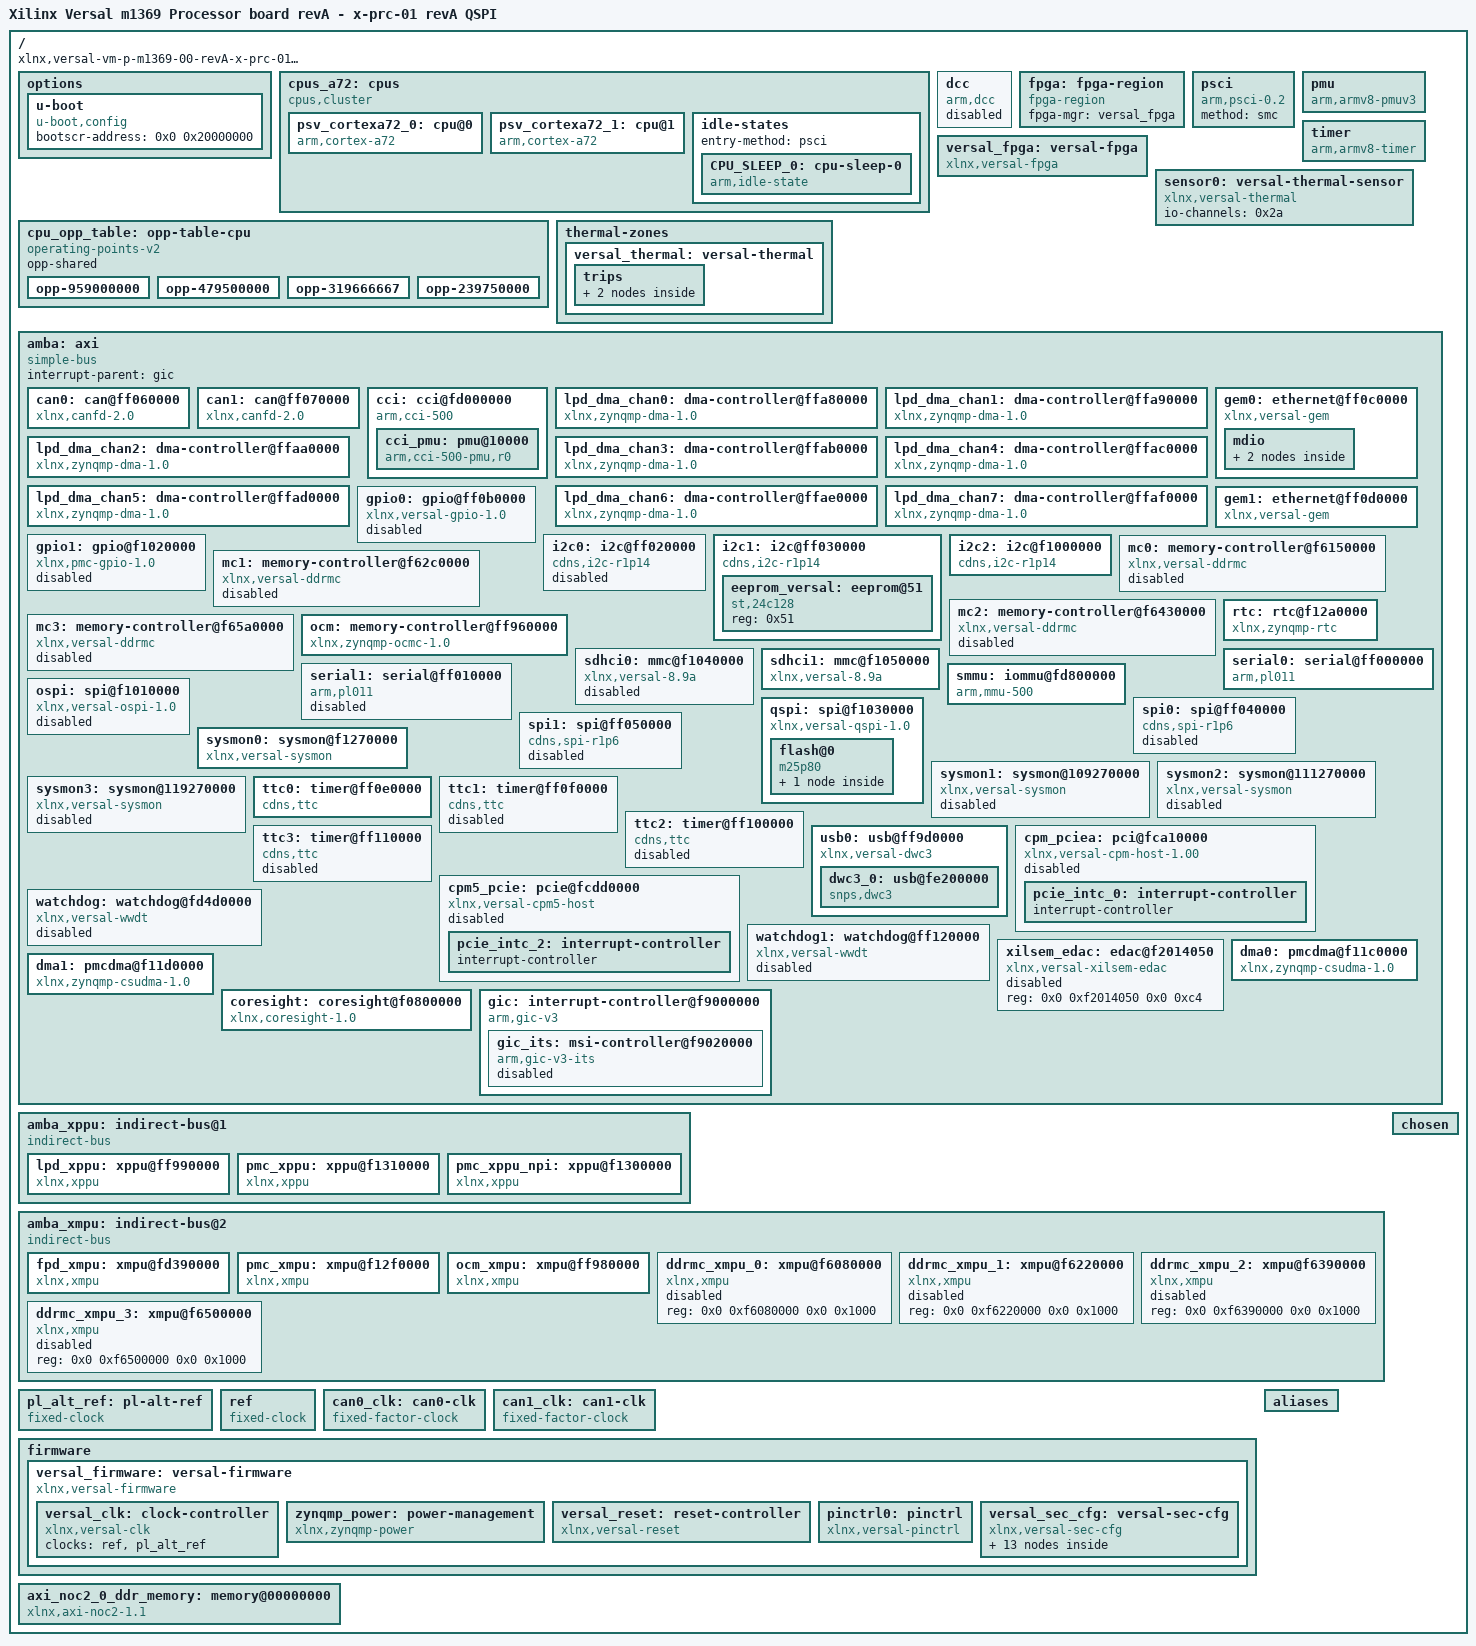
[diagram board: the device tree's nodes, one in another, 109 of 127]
/dts-v1/;
/ {
        compatible = "xlnx,versal-vm-p-m1369-00-revA-x-prc-01-revA", "xlnx,versal-vm-p-m1369-00-revA", "xlnx,versal-vm-p-m1369-00", "xlnx,versal-vm-p-m1369", "xlnx,versal";
        #address-cells = <0x2>;
        #size-cells = <0x2>;
        model = "Xilinx Versal m1369 Processor board revA - x-prc-01 revA QSPI";
        device_id = "xcvm2152";
        slrcount = <0x1>;
        family = "Versal";
        speed_grade = "1LP";

        options {

                u-boot {
                        compatible = "u-boot,config";
                        bootscr-address = <0x0 0x20000000>;
                };
        };

        cpus_a72: cpus {
                #address-cells = <0x1>;
                #size-cells = <0x0>;
                compatible = "cpus,cluster";
                #ranges-address-cells = <0x2>;
                #ranges-size-cells = <0x2>;
                phandle = <0x88>;

                psv_cortexa72_0: cpu@0 {
                        compatible = "arm,cortex-a72", "arm,armv8";
                        device_type = "cpu";
                        enable-method = "psci";
                        operating-points-v2 = <&cpu_opp_table>;
                        reg = <0x0>;
                        cpu-idle-states = <&CPU_SLEEP_0>;
                        power-domains = <&versal_firmware 0x18110003>;
                        clocks = <&versal_clk 0x4d>;
                        xlnx,timestamp-clk-freq = <0x2faf0800>;
                        xlnx,pss-ref-clk-freq = <0x1fc9f08>;
                        stamp-frequency = <0x2faf0800>;
                        xlnx,ip-name = "psv_cortexa72";
                        xlnx,cpu-clk-freq-hz = <0x2faf0800>;
                        cpu-frequency = <0x2faf0800>;
                        bus-handle = <0x1>;
                        phandle = <0x89>;
                };

                psv_cortexa72_1: cpu@1 {
                        compatible = "arm,cortex-a72", "arm,armv8";
                        device_type = "cpu";
                        enable-method = "psci";
                        operating-points-v2 = <&cpu_opp_table>;
                        reg = <0x1>;
                        cpu-idle-states = <&CPU_SLEEP_0>;
                        power-domains = <&versal_firmware 0x18110004>;
                        xlnx,timestamp-clk-freq = <0x2faf0800>;
                        xlnx,pss-ref-clk-freq = <0x1fc9f08>;
                        stamp-frequency = <0x2faf0800>;
                        xlnx,ip-name = "psv_cortexa72";
                        xlnx,cpu-clk-freq-hz = <0x2faf0800>;
                        cpu-frequency = <0x2faf0800>;
                        bus-handle = <0x1>;
                        phandle = <0x8a>;
                };

                idle-states {
                        entry-method = "psci";

                        CPU_SLEEP_0: cpu-sleep-0 {
                                compatible = "arm,idle-state";
                                arm,psci-suspend-param = <0x40000000>;
                                local-timer-stop;
                                entry-latency-us = <0x12c>;
                                exit-latency-us = <0x258>;
                                min-residency-us = <0x2710>;
                                phandle = <0x62>;
                        };
                };
        };

        cpu_opp_table: opp-table-cpu {
                compatible = "operating-points-v2";
                opp-shared;
                phandle = <0x61>;

                opp-959000000 {
                        opp-hz = <0x0 0x39292dc0>;
                        clock-latency-ns = <0x7a120>;
                        opp-microvolt = <0xf4240>;
                };

                opp-479500000 {
                        opp-hz = <0x0 0x1c9496e0>;
                        clock-latency-ns = <0x7a120>;
                        opp-microvolt = <0xf4240>;
                };

                opp-319666667 {
                        opp-hz = <0x0 0x130db9eb>;
                        clock-latency-ns = <0x7a120>;
                        opp-microvolt = <0xf4240>;
                };

                opp-239750000 {
                        opp-hz = <0x0 0xe4a4b70>;
                        clock-latency-ns = <0x7a120>;
                        opp-microvolt = <0xf4240>;
                };
        };

        dcc: dcc {
                compatible = "arm,dcc";
                status = "disabled";
                bootph-all;
                phandle = <0x93>;
        };

        fpga: fpga-region {
                compatible = "fpga-region";
                fpga-mgr = <&versal_fpga>;
                #address-cells = <0x2>;
                #size-cells = <0x2>;
                phandle = <0x94>;
        };

        psci: psci {
                compatible = "arm,psci-0.2";
                method = "smc";
                phandle = <0x95>;
        };

        pmu {
                compatible = "arm,armv8-pmuv3";
                interrupt-parent = <&gic>;
                interrupts = <0x1 0x7 0x304>;
        };

        timer: timer {
                compatible = "arm,armv8-timer";
                interrupt-parent = <&gic>;
                interrupts = <0x1 0xd 0x4 0x1 0xe 0x4 0x1 0xb 0x4 0x1 0xa 0x4>;
                phandle = <0x96>;
        };

        versal_fpga: versal-fpga {
                compatible = "xlnx,versal-fpga";
                phandle = <0x7b>;
        };

        sensor0: versal-thermal-sensor {
                compatible = "xlnx,versal-thermal";
                #thermal-sensor-cells = <0x0>;
                io-channels = <0x2a>;
                io-channel-names = "sysmon-temp-channel";
                phandle = <0x7d>;
        };

        thermal-zones {

                versal_thermal: versal-thermal {
                        polling-delay-passive = <0xfa>;
                        polling-delay = <0x3e8>;
                        thermal-sensors = <0x7d>;
                        phandle = <0x97>;

                        trips {

                                temp_alert: temp-alert {
                                        temperature = <0x11170>;
                                        hysteresis = <0x0>;
                                        type = "passive";
                                        phandle = <0x98>;
                                };

                                ot_crit: ot-crit {
                                        temperature = <0x1e848>;
                                        hysteresis = <0x0>;
                                        type = "critical";
                                        phandle = <0x99>;
                                };
                        };
                };
        };

        amba: axi {
                compatible = "simple-bus";
                #address-cells = <0x2>;
                #size-cells = <0x2>;
                ranges;
                interrupt-parent = <&gic>;
                bootph-all;
                phandle = <0x1>;

                can0: can@ff060000 {
                        compatible = "xlnx,canfd-2.0";
                        status = "okay";
                        reg = <0x0 0xff060000 0x0 0x6000>;
                        interrupts = <0x0 0x14 0x4>;
                        interrupt-parent = <&gic>;
                        clock-names = "can_clk", "s_axi_aclk";
                        rx-fifo-depth = <0x40>;
                        tx-mailbox-count = <0x20>;
                        clocks = <&can0_clk>,
                         <&versal_clk 0x52>;
                        power-domains = <&versal_firmware 0x1822401f>;
                        xlnx,can-rx-dpth = <0x40>;
                        xlnx,num-of-rx-mb-buf = <0x30>;
                        xlnx,can-clk-freq-hz = <0x98524b3>;
                        xlnx,ip-name = "psv_canfd";
                        xlnx,rx-mode = <0x0>;
                        xlnx,can-tx-dpth = <0x20>;
                        xlnx,num-of-tx-buf = <0x20>;
                        xlnx,can-board-interface = "custom";
                        phandle = <0x43>;
                };

                can1: can@ff070000 {
                        compatible = "xlnx,canfd-2.0";
                        status = "okay";
                        reg = <0x0 0xff070000 0x0 0x6000>;
                        interrupts = <0x0 0x15 0x4>;
                        interrupt-parent = <&gic>;
                        clock-names = "can_clk", "s_axi_aclk";
                        rx-fifo-depth = <0x40>;
                        tx-mailbox-count = <0x20>;
                        clocks = <&can1_clk>,
                         <&versal_clk 0x52>;
                        power-domains = <&versal_firmware 0x18224020>;
                        xlnx,can-rx-dpth = <0x40>;
                        xlnx,num-of-rx-mb-buf = <0x30>;
                        xlnx,can-clk-freq-hz = <0x98524b3>;
                        xlnx,ip-name = "psv_canfd";
                        xlnx,rx-mode = <0x0>;
                        xlnx,can-tx-dpth = <0x20>;
                        xlnx,num-of-tx-buf = <0x20>;
                        xlnx,can-board-interface = "custom";
                        phandle = <0x44>;
                };

                cci: cci@fd000000 {
                        compatible = "arm,cci-500";
                        status = "okay";
                        reg = <0x0 0xfd000000 0x0 0x10000>;
                        ranges = <0x0 0x0 0xfd000000 0xa0000>;
                        #address-cells = <0x1>;
                        #size-cells = <0x1>;
                        xlnx,ip-name = "psv_fpd_maincci";
                        phandle = <0x34>;

                        cci_pmu: pmu@10000 {
                                compatible = "arm,cci-500-pmu,r0";
                                reg = <0x10000 0x90000>;
                                interrupt-parent = <&gic>;
                                interrupts = <0x0 0x6a 0x4 0x0 0x6a 0x4 0x0 0x6a 0x4 0x0 0x6a 0x4 0x0 0x6a 0x4 0x0 0x6a 0x4 0x0 0x6a 0x4 0x0 0x6a 0x4>;
                                phandle = <0x9a>;
                        };
                };

                lpd_dma_chan0: dma-controller@ffa80000 {
                        compatible = "xlnx,zynqmp-dma-1.0";
                        status = "okay";
                        reg = <0x0 0xffa80000 0x0 0x1000>;
                        interrupts = <0x0 0x3c 0x4>;
                        interrupt-parent = <&gic>;
                        clock-names = "clk_main", "clk_apb";
                        xlnx,dma-type = <0x1>;
                        #dma-cells = <0x1>;
                        xlnx,bus-width = <0x40>;
                        clocks = <&versal_clk 0x51>,
                         <&versal_clk 0x52>;
                        power-domains = <&versal_firmware 0x18224035>;
                        xlnx,is-cache-coherent = <0x0>;
                        xlnx,ip-name = "psv_adma";
                        xlnx,dma-mode = <0x1>;
                        phandle = <0x55>;
                };

                lpd_dma_chan1: dma-controller@ffa90000 {
                        compatible = "xlnx,zynqmp-dma-1.0";
                        status = "okay";
                        reg = <0x0 0xffa90000 0x0 0x1000>;
                        interrupts = <0x0 0x3d 0x4>;
                        interrupt-parent = <&gic>;
                        clock-names = "clk_main", "clk_apb";
                        xlnx,dma-type = <0x1>;
                        #dma-cells = <0x1>;
                        xlnx,bus-width = <0x40>;
                        clocks = <&versal_clk 0x51>,
                         <&versal_clk 0x52>;
                        power-domains = <&versal_firmware 0x18224036>;
                        xlnx,is-cache-coherent = <0x0>;
                        xlnx,ip-name = "psv_adma";
                        xlnx,dma-mode = <0x1>;
                        phandle = <0x56>;
                };

                lpd_dma_chan2: dma-controller@ffaa0000 {
                        compatible = "xlnx,zynqmp-dma-1.0";
                        status = "okay";
                        reg = <0x0 0xffaa0000 0x0 0x1000>;
                        interrupts = <0x0 0x3e 0x4>;
                        interrupt-parent = <&gic>;
                        clock-names = "clk_main", "clk_apb";
                        xlnx,dma-type = <0x1>;
                        #dma-cells = <0x1>;
                        xlnx,bus-width = <0x40>;
                        clocks = <&versal_clk 0x51>,
                         <&versal_clk 0x52>;
                        power-domains = <&versal_firmware 0x18224037>;
                        xlnx,is-cache-coherent = <0x0>;
                        xlnx,ip-name = "psv_adma";
                        xlnx,dma-mode = <0x1>;
                        phandle = <0x57>;
                };

                lpd_dma_chan3: dma-controller@ffab0000 {
                        compatible = "xlnx,zynqmp-dma-1.0";
                        status = "okay";
                        reg = <0x0 0xffab0000 0x0 0x1000>;
                        interrupts = <0x0 0x3f 0x4>;
                        interrupt-parent = <&gic>;
                        clock-names = "clk_main", "clk_apb";
                        xlnx,dma-type = <0x1>;
                        #dma-cells = <0x1>;
                        xlnx,bus-width = <0x40>;
                        clocks = <&versal_clk 0x51>,
                         <&versal_clk 0x52>;
                        power-domains = <&versal_firmware 0x18224038>;
                        xlnx,is-cache-coherent = <0x0>;
                        xlnx,ip-name = "psv_adma";
                        xlnx,dma-mode = <0x1>;
                        phandle = <0x58>;
                };

                lpd_dma_chan4: dma-controller@ffac0000 {
                        compatible = "xlnx,zynqmp-dma-1.0";
                        status = "okay";
                        reg = <0x0 0xffac0000 0x0 0x1000>;
                        interrupts = <0x0 0x40 0x4>;
                        interrupt-parent = <&gic>;
                        clock-names = "clk_main", "clk_apb";
                        xlnx,dma-type = <0x1>;
                        #dma-cells = <0x1>;
                        xlnx,bus-width = <0x40>;
                        clocks = <&versal_clk 0x51>,
                         <&versal_clk 0x52>;
                        power-domains = <&versal_firmware 0x18224039>;
                        xlnx,is-cache-coherent = <0x0>;
                        xlnx,ip-name = "psv_adma";
                        xlnx,dma-mode = <0x1>;
                        phandle = <0x59>;
                };

                lpd_dma_chan5: dma-controller@ffad0000 {
                        compatible = "xlnx,zynqmp-dma-1.0";
                        status = "okay";
                        reg = <0x0 0xffad0000 0x0 0x1000>;
                        interrupts = <0x0 0x41 0x4>;
                        interrupt-parent = <&gic>;
                        clock-names = "clk_main", "clk_apb";
                        xlnx,dma-type = <0x1>;
                        #dma-cells = <0x1>;
                        xlnx,bus-width = <0x40>;
                        clocks = <&versal_clk 0x51>,
                         <&versal_clk 0x52>;
                        power-domains = <&versal_firmware 0x1822403a>;
                        xlnx,is-cache-coherent = <0x0>;
                        xlnx,ip-name = "psv_adma";
                        xlnx,dma-mode = <0x1>;
                        phandle = <0x5a>;
                };

                lpd_dma_chan6: dma-controller@ffae0000 {
                        compatible = "xlnx,zynqmp-dma-1.0";
                        status = "okay";
                        reg = <0x0 0xffae0000 0x0 0x1000>;
                        interrupts = <0x0 0x42 0x4>;
                        interrupt-parent = <&gic>;
                        clock-names = "clk_main", "clk_apb";
                        xlnx,dma-type = <0x1>;
                        #dma-cells = <0x1>;
                        xlnx,bus-width = <0x40>;
                        clocks = <&versal_clk 0x51>,
                         <&versal_clk 0x52>;
                        power-domains = <&versal_firmware 0x1822403b>;
                        xlnx,is-cache-coherent = <0x0>;
                        xlnx,ip-name = "psv_adma";
                        xlnx,dma-mode = <0x1>;
                        phandle = <0x5b>;
                };

                lpd_dma_chan7: dma-controller@ffaf0000 {
                        compatible = "xlnx,zynqmp-dma-1.0";
                        status = "okay";
                        reg = <0x0 0xffaf0000 0x0 0x1000>;
                        interrupts = <0x0 0x43 0x4>;
                        interrupt-parent = <&gic>;
                        clock-names = "clk_main", "clk_apb";
                        xlnx,dma-type = <0x1>;
                        #dma-cells = <0x1>;
                        xlnx,bus-width = <0x40>;
                        clocks = <&versal_clk 0x51>,
                         <&versal_clk 0x52>;
                        power-domains = <&versal_firmware 0x1822403c>;
                        xlnx,is-cache-coherent = <0x0>;
                        xlnx,ip-name = "psv_adma";
                        xlnx,dma-mode = <0x1>;
                        phandle = <0x5c>;
                };

                gem0: ethernet@ff0c0000 {
                        compatible = "xlnx,versal-gem", "cdns,gem";
                        status = "okay";
                        reg = <0x0 0xff0c0000 0x0 0x1000>;
                        interrupts = <0x0 0x38 0x4 0x0 0x38 0x4>;
                        interrupt-parent = <&gic>;
                        clock-names = "pclk", "hclk", "tx_clk", "rx_clk", "tsu_clk";
                        #address-cells = <0x1>;
                        #size-cells = <0x0>;
                        clocks = <&versal_clk 0x52>,
                         <&versal_clk 0x58>,
                         <&versal_clk 0x31>,
                         <&versal_clk 0x30>,
                         <&versal_clk 0x2b>;
                        power-domains = <&versal_firmware 0x18224019>;
                        xlnx,has-mdio = <0x1>;
                        xlnx,is-cache-coherent = <0x0>;
                        xlnx,gem-board-interface = "custom";
                        phy-mode = "rgmii-id";
                        xlnx,enet-slcr-1000mbps-div0 = <0x7>;
                        xlnx,enet-slcr-10mbps-div0 = <0x15e>;
                        xlnx,enet-tsu-clk-freq-hz = <0xe47b705>;
                        xlnx,ip-name = "psv_ethernet";
                        xlnx,eth-mode = "RGMII";
                        xlnx,enet-clk-freq-hz = <0x7735464>;
                        xlnx,enet-slcr-100mbps-div0 = <0x23>;
                        phy-handle = <0x80>;
                        phandle = <0x47>;

                        mdio: mdio {
                                #address-cells = <0x1>;
                                #size-cells = <0x0>;
                                phandle = <0x9b>;

                                phy1: phy@1 {
                                        #phy-cells = <0x1>;
                                        compatible = "ethernet-phy-id2000.a231";
                                        reg = <0x1>;
                                        ti,rx-internal-delay = <0xb>;
                                        ti,tx-internal-delay = <0xa>;
                                        ti,fifo-depth = <0x1>;
                                        ti,dp83867-rxctrl-strap-quirk;
                                        phandle = <0x80>;
                                };

                                phy2: phy@2 {
                                        #phy-cells = <0x1>;
                                        compatible = "ethernet-phy-id2000.a231";
                                        reg = <0x2>;
                                        ti,rx-internal-delay = <0xb>;
                                        ti,tx-internal-delay = <0xa>;
                                        ti,fifo-depth = <0x1>;
                                        ti,dp83867-rxctrl-strap-quirk;
                                        phandle = <0x81>;
                                };
                        };
                };

                gem1: ethernet@ff0d0000 {
                        compatible = "xlnx,versal-gem", "cdns,gem";
                        status = "okay";
                        reg = <0x0 0xff0d0000 0x0 0x1000>;
                        interrupts = <0x0 0x3a 0x4 0x0 0x3a 0x4>;
                        interrupt-parent = <&gic>;
                        clock-names = "pclk", "hclk", "tx_clk", "rx_clk", "tsu_clk";
                        #address-cells = <0x1>;
                        #size-cells = <0x0>;
                        clocks = <&versal_clk 0x52>,
                         <&versal_clk 0x59>,
                         <&versal_clk 0x33>,
                         <&versal_clk 0x32>,
                         <&versal_clk 0x2b>;
                        power-domains = <&versal_firmware 0x1822401a>;
                        xlnx,has-mdio = <0x0>;
                        xlnx,is-cache-coherent = <0x0>;
                        xlnx,gem-board-interface = "custom";
                        phy-mode = "rgmii-id";
                        xlnx,enet-slcr-1000mbps-div0 = <0x7>;
                        xlnx,enet-slcr-10mbps-div0 = <0x15e>;
                        xlnx,enet-tsu-clk-freq-hz = <0xe47b705>;
                        xlnx,ip-name = "psv_ethernet";
                        xlnx,eth-mode = "RGMII";
                        xlnx,enet-clk-freq-hz = <0x7735464>;
                        xlnx,enet-slcr-100mbps-div0 = <0x23>;
                        phy-handle = <0x81>;
                        phandle = <0x48>;
                };

                gpio0: gpio@ff0b0000 {
                        compatible = "xlnx,versal-gpio-1.0";
                        status = "disabled";
                        reg = <0x0 0xff0b0000 0x0 0x1000>;
                        interrupts = <0x0 0xd 0x4>;
                        interrupt-parent = <&gic>;
                        #gpio-cells = <0x2>;
                        gpio-controller;
                        #interrupt-cells = <0x2>;
                        interrupt-controller;
                        clocks = <&versal_clk 0x52>;
                        power-domains = <&versal_firmware 0x18224023>;
                        phandle = <0x9c>;
                };

                gpio1: gpio@f1020000 {
                        compatible = "xlnx,pmc-gpio-1.0";
                        status = "disabled";
                        reg = <0x0 0xf1020000 0x0 0x1000>;
                        interrupts = <0x0 0x7a 0x4>;
                        interrupt-parent = <&gic>;
                        #gpio-cells = <0x2>;
                        gpio-controller;
                        #interrupt-cells = <0x2>;
                        interrupt-controller;
                        clocks = <&versal_clk 0x3d>;
                        power-domains = <&versal_firmware 0x1822402c>;
                        phandle = <0x9d>;
                };

                i2c0: i2c@ff020000 {
                        compatible = "cdns,i2c-r1p14";
                        status = "disabled";
                        reg = <0x0 0xff020000 0x0 0x1000>;
                        interrupts = <0x0 0xe 0x4>;
                        interrupt-parent = <&gic>;
                        clock-frequency = <0x186a0>;
                        #address-cells = <0x1>;
                        #size-cells = <0x0>;
                        clocks = <&versal_clk 0x62>;
                        power-domains = <&versal_firmware 0x1822401d>;
                        phandle = <0x9e>;
                };

                i2c1: i2c@ff030000 {
                        compatible = "cdns,i2c-r1p14";
                        status = "okay";
                        reg = <0x0 0xff030000 0x0 0x1000>;
                        interrupts = <0x0 0xf 0x4>;
                        interrupt-parent = <&gic>;
                        clock-frequency = <0x61a80>;
                        #address-cells = <0x1>;
                        #size-cells = <0x0>;
                        clocks = <&versal_clk 0x63>;
                        power-domains = <&versal_firmware 0x1822401e>;
                        xlnx,clock-freq = <0x5f5dd19>;
                        xlnx,i2c-clk-freq-hz = <0x5f5dd19>;
                        xlnx,ip-name = "psv_i2c";
                        xlnx,iic-board-interface = "custom";
                        phandle = <0x42>;

                        eeprom_versal: eeprom@51 {
                                compatible = "st,24c128", "atmel,24c128";
                                reg = <0x51>;
                                phandle = <0x9f>;
                        };
                };

                i2c2: i2c@f1000000 {
                        compatible = "cdns,i2c-r1p14";
                        status = "okay";
                        reg = <0x0 0xf1000000 0x0 0x1000>;
                        interrupts = <0x0 0x7b 0x4>;
                        interrupt-parent = <&gic>;
                        clock-frequency = <0x186a0>;
                        #address-cells = <0x1>;
                        #size-cells = <0x0>;
                        clocks = <&versal_clk 0x3e>;
                        power-domains = <&versal_firmware 0x1822402d>;
                        xlnx,clock-freq = <0x5f5dd19>;
                        xlnx,i2c-clk-freq-hz = <0x5f5dd19>;
                        xlnx,ip-name = "psv_pmc_i2c";
                        phandle = <0x1b>;
                };

                mc0: memory-controller@f6150000 {
                        compatible = "xlnx,versal-ddrmc";
                        status = "disabled";
                        reg = <0x0 0xf6150000 0x0 0x2000 0x0 0xf6070000 0x0 0x20000>;
                        reg-names = "base", "noc";
                        interrupts = <0x0 0x93 0x4>;
                        interrupt-parent = <&gic>;
                        phandle = <0xa0>;
                };

                mc1: memory-controller@f62c0000 {
                        compatible = "xlnx,versal-ddrmc";
                        status = "disabled";
                        reg = <0x0 0xf62c0000 0x0 0x2000 0x0 0xf6210000 0x0 0x20000>;
                        reg-names = "base", "noc";
                        interrupts = <0x0 0x93 0x4>;
                        interrupt-parent = <&gic>;
                        phandle = <0xa1>;
                };

                mc2: memory-controller@f6430000 {
                        compatible = "xlnx,versal-ddrmc";
                        status = "disabled";
                        reg = <0x0 0xf6430000 0x0 0x2000 0x0 0xf6380000 0x0 0x20000>;
                        reg-names = "base", "noc";
                        interrupts = <0x0 0x93 0x4>;
                        interrupt-parent = <&gic>;
                        phandle = <0xa2>;
                };

                mc3: memory-controller@f65a0000 {
                        compatible = "xlnx,versal-ddrmc";
                        status = "disabled";
                        reg = <0x0 0xf65a0000 0x0 0x2000 0x0 0xf64f0000 0x0 0x20000>;
                        reg-names = "base", "noc";
                        interrupts = <0x0 0x93 0x4>;
                        interrupt-parent = <&gic>;
                        phandle = <0xa3>;
                };

                ocm: memory-controller@ff960000 {
                        compatible = "xlnx,zynqmp-ocmc-1.0";
                        reg = <0x0 0xff960000 0x0 0x1000>;
                        interrupts = <0x0 0xa 0x4>;
                        interrupt-parent = <&gic>;
                        phandle = <0xa4>;
                };

                rtc: rtc@f12a0000 {
                        compatible = "xlnx,zynqmp-rtc";
                        status = "okay";
                        reg = <0x0 0xf12a0000 0x0 0x100>;
                        interrupt-names = "alarm", "sec";
                        interrupts = <0x0 0x8e 0x4 0x0 0x8f 0x4>;
                        interrupt-parent = <&gic>;
                        calibration = <0x7fff>;
                        power-domains = <&versal_firmware 0x18224034>;
                        xlnx,ip-name = "psv_pmc_rtc";
                        phandle = <0x2b>;
                };

                sdhci0: mmc@f1040000 {
                        compatible = "xlnx,versal-8.9a", "arasan,sdhci-8.9a";
                        status = "disabled";
                        reg = <0x0 0xf1040000 0x0 0x10000>;
                        interrupts = <0x0 0x7e 0x4>;
                        interrupt-parent = <&gic>;
                        clock-names = "clk_xin", "clk_ahb", "gate";
                        #clock-cells = <0x1>;
                        clock-output-names = "clk_out_sd0", "clk_in_sd0";
                        clocks = <&versal_clk 0x3b>,
                         <&versal_clk 0x52>,
                         <&versal_clk 0x4a>;
                        power-domains = <&versal_firmware 0x1822402e>;
                        no-1-8-v;
                        phandle = <0xa5>;
                };

                sdhci1: mmc@f1050000 {
                        compatible = "xlnx,versal-8.9a", "arasan,sdhci-8.9a";
                        status = "okay";
                        reg = <0x0 0xf1050000 0x0 0x10000>;
                        interrupts = <0x0 0x80 0x4>;
                        interrupt-parent = <&gic>;
                        clock-names = "clk_xin", "clk_ahb", "gate";
                        #clock-cells = <0x1>;
                        clock-output-names = "clk_out_sd1", "clk_in_sd1";
                        clocks = <&versal_clk 0x3c>,
                         <&versal_clk 0x52>,
                         <&versal_clk 0x4a>;
                        power-domains = <&versal_firmware 0x1822402f>;
                        xlnx,sd-board-interface = "custom";
                        xlnx,is-cache-coherent = <0x0>;
                        xlnx,clk-50-ddr-otap-dly = <0x3>;
                        xlnx,clk-50-sdr-itap-dly = <0x2c>;
                        xlnx,has-emio = <0x0>;
                        clock-frequency = <0xbebba31>;
                        xlnx,clk-100-sdr-otap-dly = <0x3>;
                        xlnx,mio-bank = <0x1>;
                        xlnx,ip-name = "psv_pmc_sd";
                        xlnx,bus-width = <0x8>;
                        xlnx,card-detect = <0x1>;
                        xlnx,has-wp = <0x1>;
                        xlnx,has-cd = <0x1>;
                        xlnx,slot-type = <0x3>;
                        xlnx,clk-50-sdr-otap-dly = <0x4>;
                        xlnx,clk-50-ddr-itap-dly = <0x36>;
                        xlnx,has-power = <0x1>;
                        xlnx,clk-200-sdr-otap-dly = <0x2>;
                        xlnx,sdio-clk-freq-hz = <0xbebba31>;
                        xlnx,write-protect = <0x1>;
                        no-1-8-v;
                        phandle = <0x1d>;
                };

                serial0: serial@ff000000 {
                        compatible = "arm,pl011", "arm,primecell";
                        status = "okay";
                        reg = <0x0 0xff000000 0x0 0x1000>;
                        interrupts = <0x0 0x12 0x4>;
                        interrupt-parent = <&gic>;
                        reg-io-width = <0x4>;
                        clock-names = "uartclk", "apb_pclk";
                        bootph-all;
                        clocks = <&versal_clk 0x5c>,
                         <&versal_clk 0x52>;
                        power-domains = <&versal_firmware 0x18224021>;
                        xlnx,clock-freq = <0x5f5dd19>;
                        u-boot,dm-pre-reloc;
                        xlnx,uart-board-interface = "custom";
                        xlnx,has-modem = <0x0>;
                        xlnx,ip-name = "psv_sbsauart";
                        xlnx,baudrate = <0x1c200>;
                        cts-override;
                        port-number = <0x0>;
                        xlnx,uart-clk-freq-hz = <0x5f5dd19>;
                        phandle = <0x41>;
                };

                serial1: serial@ff010000 {
                        compatible = "arm,pl011", "arm,primecell";
                        status = "disabled";
                        reg = <0x0 0xff010000 0x0 0x1000>;
                        interrupts = <0x0 0x13 0x4>;
                        interrupt-parent = <&gic>;
                        reg-io-width = <0x4>;
                        clock-names = "uartclk", "apb_pclk";
                        bootph-all;
                        clocks = <&versal_clk 0x5d>,
                         <&versal_clk 0x52>;
                        power-domains = <&versal_firmware 0x18224022>;
                        phandle = <0xa6>;
                };

                smmu: iommu@fd800000 {
                        compatible = "arm,mmu-500";
                        status = "okay";
                        reg = <0x0 0xfd800000 0x0 0x40000>;
                        stream-match-mask = <0x7c00>;
                        #iommu-cells = <0x1>;
                        #global-interrupts = <0x1>;
                        interrupts = <0x0 0x6b 0x4 0x0 0x6b 0x4 0x0 0x6b 0x4 0x0 0x6b 0x4 0x0 0x6b 0x4 0x0 0x6b 0x4 0x0 0x6b 0x4 0x0 0x6b 0x4 0x0 0x6b 0x4 0x0 0x6b 0x4 0x0 0x6b 0x4 0x0 0x6b 0x4 0x0 0x6b 0x4 0x0 0x6b 0x4 0x0 0x6b 0x4 0x0 0x6b 0x4 0x0 0x6b 0x4 0x0 0x6b 0x4 0x0 0x6b 0x4 0x0 0x6b 0x4 0x0 0x6b 0x4 0x0 0x6b 0x4 0x0 0x6b 0x4 0x0 0x6b 0x4 0x0 0x6b 0x4 0x0 0x6b 0x4 0x0 0x6b 0x4 0x0 0x6b 0x4 0x0 0x6b 0x4 0x0 0x6b 0x4 0x0 0x6b 0x4 0x0 0x6b 0x4 0x0 0x6b 0x4>;
                        interrupt-parent = <&gic>;
                        xlnx,ip-name = "psv_fpd_smmutcu";
                        phandle = <0x3f>;
                };

                ospi: spi@f1010000 {
                        compatible = "xlnx,versal-ospi-1.0", "cdns,qspi-nor";
                        status = "disabled";
                        reg = <0x0 0xf1010000 0x0 0x10000 0x0 0xc0000000 0x0 0x20000000>;
                        interrupts = <0x0 0x7c 0x4>;
                        interrupt-parent = <&gic>;
                        cdns,fifo-depth = <0x100>;
                        cdns,fifo-width = <0x4>;
                        cdns,is-dma = <0x1>;
                        cdns,trigger-address = <0xc0000000>;
                        #address-cells = <0x1>;
                        #size-cells = <0x0>;
                        clocks = <&versal_clk 0x3a>;
                        power-domains = <&versal_firmware 0x1822402a>;
                        reset-names = "qspi";
                        resets = <&versal_reset 0xc10402e>;
                        phandle = <0xa7>;
                };

                qspi: spi@f1030000 {
                        compatible = "xlnx,versal-qspi-1.0";
                        status = "okay";
                        reg = <0x0 0xf1030000 0x0 0x1000>;
                        interrupts = <0x0 0x7d 0x4>;
                        interrupt-parent = <&gic>;
                        clock-names = "ref_clk", "pclk";
                        #address-cells = <0x1>;
                        #size-cells = <0x0>;
                        clocks = <&versal_clk 0x39>,
                         <&versal_clk 0x52>;
                        power-domains = <&versal_firmware 0x1822402b>;
                        xlnx,is-cache-coherent = <0x0>;
                        xlnx,qspi-fbclk = <0x1>;
                        xlnx,baud-rate-div = <0x8>;
                        num-cs = <0x2>;
                        xlnx,qspi-clk-freq-hz = <0x11e19751>;
                        xlnx,bus-width = <0x2>;
                        xlnx,ip-name = "psv_pmc_qspi";
                        spi-rx-bus-width = <0x4>;
                        xlnx,connection-mode = <0x2>;
                        spi-tx-bus-width = <0x4>;
                        xlnx,clock-freq = <0x11e19751>;
                        xlnx,qspi-baud-rate-div = <0x8>;
                        xlnx,qspi-mode = <0x2>;
                        xlnx,qspi-bus-width = <0x2>;
                        is-dual = <0x1>;
                        phandle = <0x1c>;

                        flash@0 {
                                compatible = "m25p80", "jedec,spi-nor";
                                #address-cells = <0x1>;
                                #size-cells = <0x1>;
                                reg = <0x0 0x1>;
                                parallel-memories = <0x0 0x8000000 0x0 0x8000000>;
                                spi-tx-bus-width = <0x4>;
                                spi-rx-bus-width = <0x4>;
                                spi-max-frequency = <0x2160ec0>;

                                partition@0 {
                                        label = "spi0-flash0";
                                        reg = <0x0 0x8000000>;
                                };
                        };
                };

                spi0: spi@ff040000 {
                        compatible = "cdns,spi-r1p6";
                        status = "disabled";
                        reg = <0x0 0xff040000 0x0 0x1000>;
                        interrupts = <0x0 0x10 0x4>;
                        interrupt-parent = <&gic>;
                        clock-names = "ref_clk", "pclk";
                        #address-cells = <0x1>;
                        #size-cells = <0x0>;
                        clocks = <&versal_clk 0x5e>,
                         <&versal_clk 0x52>;
                        power-domains = <&versal_firmware 0x1822401b>;
                        phandle = <0xa8>;
                };

                spi1: spi@ff050000 {
                        compatible = "cdns,spi-r1p6";
                        status = "disabled";
                        reg = <0x0 0xff050000 0x0 0x1000>;
                        interrupts = <0x0 0x11 0x4>;
                        interrupt-parent = <&gic>;
                        clock-names = "ref_clk", "pclk";
                        #address-cells = <0x1>;
                        #size-cells = <0x0>;
                        clocks = <&versal_clk 0x5f>,
                         <&versal_clk 0x52>;
                        power-domains = <&versal_firmware 0x1822401c>;
                        phandle = <0xa9>;
                };

                sysmon0: sysmon@f1270000 {
                        compatible = "xlnx,versal-sysmon";
                        #io-channel-cells = <0x0>;
                        reg = <0x0 0xf1270000 0x0 0x4000>;
                        interrupts = <0x0 0x90 0x4>;
                        xlnx,numchannels = "";
                        #address-cells = <0x2>;
                        #size-cells = <0x2>;
                        xlnx,nodeid = <0x18224055>;
                        xlnx,sat-1-desc = "PMC , system , ADC";
                        xlnx,sat-63-desc = "PS , FPD , satellite";
                        xlnx,sat-9-x = <0x1b0b>;
                        xlnx,sat-9-y = <0x1d6e>;
                        xlnx,ip-name = "psv_pmc_sysmon";
                        xlnx,sat-9-desc = "VNOC , satellite";
                        xlnx,sat-10-x = <0x1b0b>;
                        xlnx,sat-10-y = <0x2961>;
                        xlnx,sat-2-x = <0x24>;
                        xlnx,sat-64-x = <0x24>;
                        xlnx,sat-13-desc = "Clocking , column , satellite";
                        xlnx,sat-2-y = <0xea8>;
                        xlnx,sat-64-y = <0xea8>;
                        xlnx,sat-14-x = <0xb78>;
                        xlnx,sat-6-desc = "VNOC , satellite";
                        xlnx,sat-14-y = <0x1b09>;
                        xlnx,sat-6-x = <0x30dd>;
                        xlnx,sat-6-y = <0x2961>;
                        xlnx,sat-10-desc = "VNOC , satellite";
                        xlnx,sat-3-desc = "X5IO , Satellite";
                        xlnx,sat-11-x = <0xb78>;
                        xlnx,sat-11-y = <0x2d2c>;
                        xlnx,sat-3-x = <0xddd>;
                        status = "okay";
                        xlnx,sat-3-y = <0x90c>;
                        xlnx,sat-7-x = <0x2898>;
                        xlnx,sat-8-desc = "VNOC , satellite";
                        xlnx,sat-7-y = <0x90c>;
                        xlnx,sat-12-desc = "Clocking , column , satellite";
                        xlnx,sat-5-desc = "VNOC , satellite";
                        xlnx,sat-2-desc = "PMC , user , ADC";
                        xlnx,sat-64-desc = "PS , LPD , satellite";
                        xlnx,sat-12-x = <0xb78>;
                        xlnx,sat-12-y = <0x26fd>;
                        xlnx,sat-4-x = <0x30dd>;
                        xlnx,sat-4-y = <0x117a>;
                        xlnx,sat-8-x = <0x1b0b>;
                        xlnx,sat-8-y = <0x117a>;
                        xlnx,sat-14-desc = "Clocking , column , satellite";
                        xlnx,sat-7-desc = "X5IO , Satellite";
                        xlnx,sat-11-desc = "Clocking , column , satellite";
                        xlnx,sat-1-x = <0x24>;
                        xlnx,sat-63-x = <0x24>;
                        xlnx,sat-1-y = <0xea8>;
                        xlnx,sat-63-y = <0xea8>;
                        xlnx,sat-4-desc = "VNOC , satellite";
                        xlnx,sat-13-x = <0xb78>;
                        xlnx,sat-13-y = <0x2138>;
                        xlnx,sat-5-x = <0x30dd>;
                        xlnx,sat-5-y = <0x1d6e>;
                        phandle = <0x2a>;
                };

                sysmon1: sysmon@109270000 {
                        compatible = "xlnx,versal-sysmon";
                        status = "disabled";
                        reg = <0x1 0x9270000 0x0 0x4000>;
                        xlnx,numchannels = "";
                        #address-cells = <0x1>;
                        #size-cells = <0x0>;
                        xlnx,nodeid = <0x18225055>;
                        phandle = <0xaa>;
                };

                sysmon2: sysmon@111270000 {
                        compatible = "xlnx,versal-sysmon";
                        status = "disabled";
                        reg = <0x1 0x11270000 0x0 0x4000>;
                        xlnx,numchannels = "";
                        #address-cells = <0x1>;
                        #size-cells = <0x0>;
                        xlnx,nodeid = <0x18226055>;
                        phandle = <0xab>;
                };

                sysmon3: sysmon@119270000 {
                        compatible = "xlnx,versal-sysmon";
                        status = "disabled";
                        reg = <0x1 0x19270000 0x0 0x4000>;
                        xlnx,numchannels = "";
                        #address-cells = <0x1>;
                        #size-cells = <0x0>;
                        xlnx,nodeid = <0x18227055>;
                        phandle = <0xac>;
                };

                ttc0: timer@ff0e0000 {
                        compatible = "cdns,ttc";
                        status = "okay";
                        interrupts = <0x0 0x25 0x4 0x0 0x26 0x4 0x0 0x27 0x4>;
                        interrupt-parent = <&gic>;
                        reg = <0x0 0xff0e0000 0x0 0x1000>;
                        timer-width = <0x20>;
                        clocks = <&versal_clk 0x27>;
                        power-domains = <&versal_firmware 0x18224024>;
                        xlnx,ttc-board-interface = "custom";
                        xlnx,ttc-clk2-freq-hz = <0x5f5dd19>;
                        xlnx,ttc-clk1-clksrc = <0x1>;
                        xlnx,clock-freq = <0x5f5dd19>;
                        xlnx,ttc-clk2-clksrc = <0x1>;
                        xlnx,ip-name = "psv_ttc";
                        xlnx,ttc-clk0-freq-hz = <0x5f5dd19>;
                        xlnx,ttc-clk1-freq-hz = <0x5f5dd19>;
                        xlnx,ttc-clk0-clksrc = <0x1>;
                        phandle = <0x49>;
                };

                ttc1: timer@ff0f0000 {
                        compatible = "cdns,ttc";
                        status = "disabled";
                        interrupts = <0x0 0x28 0x4 0x0 0x29 0x4 0x0 0x2a 0x4>;
                        interrupt-parent = <&gic>;
                        reg = <0x0 0xff0f0000 0x0 0x1000>;
                        timer-width = <0x20>;
                        clocks = <&versal_clk 0x28>;
                        power-domains = <&versal_firmware 0x18224025>;
                        phandle = <0xad>;
                };

                ttc2: timer@ff100000 {
                        compatible = "cdns,ttc";
                        status = "disabled";
                        interrupts = <0x0 0x2b 0x4 0x0 0x2c 0x4 0x0 0x2d 0x4>;
                        interrupt-parent = <&gic>;
                        reg = <0x0 0xff100000 0x0 0x1000>;
                        timer-width = <0x20>;
                        clocks = <&versal_clk 0x29>;
                        power-domains = <&versal_firmware 0x18224026>;
                        phandle = <0xae>;
                };

                ttc3: timer@ff110000 {
                        compatible = "cdns,ttc";
                        status = "disabled";
                        interrupts = <0x0 0x2e 0x4 0x0 0x2f 0x4 0x0 0x30 0x4>;
                        interrupt-parent = <&gic>;
                        reg = <0x0 0xff110000 0x0 0x1000>;
                        timer-width = <0x20>;
                        clocks = <&versal_clk 0x2a>;
                        power-domains = <&versal_firmware 0x18224027>;
                        phandle = <0xaf>;
                };

                usb0: usb@ff9d0000 {
                        compatible = "xlnx,versal-dwc3";
                        status = "okay";
                        reg = <0x0 0xff9d0000 0x0 0x100>;
                        clock-names = "bus_clk", "ref_clk";
                        ranges;
                        #address-cells = <0x2>;
                        #size-cells = <0x2>;
                        clocks = <&versal_clk 0x5b>,
                         <&versal_clk 0x68>;
                        power-domains = <&versal_firmware 0x18224018>;
                        resets = <&versal_reset 0xc104036>;
                        xlnx,ip-name = "psv_usb";
                        phandle = <0x54>;

                        dwc3_0: usb@fe200000 {
                                compatible = "snps,dwc3";
                                status = "okay";
                                reg = <0x0 0xfe200000 0x0 0x10000>;
                                interrupt-names = "host", "peripheral", "otg", "wakeup";
                                interrupts = <0x0 0x16 0x4 0x0 0x16 0x4 0x0 0x1a 0x4 0x0 0x4a 0x4>;
                                interrupt-parent = <&gic>;
                                snps,dis_u2_susphy_quirk;
                                snps,dis_u3_susphy_quirk;
                                snps,quirk-frame-length-adjustment = <0x20>;
                                clock-names = "ref";
                                clocks = <&versal_clk 0x5b>;
                                xlnx,is-cache-coherent = <0x0>;
                                xlnx,ip-name = "psv_usb_xhci";
                                xlnx,enable-superspeed = <0x0>;
                                dr_mode = "host";
                                maximum-speed = "high-speed";
                                snps,usb3_lpm_capable;
                                phy-names = "usb3-phy";
                                phandle = <0x40>;
                        };
                };

                cpm_pciea: pci@fca10000 {
                        device_type = "pci";
                        #address-cells = <0x3>;
                        #interrupt-cells = <0x1>;
                        #size-cells = <0x2>;
                        compatible = "xlnx,versal-cpm-host-1.00";
                        status = "disabled";
                        interrupt-map = <0x0 0x0 0x0 0x1 &pcie_intc_0 0x0>,
                         <0x0 0x0 0x0 0x2 &pcie_intc_0 0x1>,
                         <0x0 0x0 0x0 0x3 &pcie_intc_0 0x2>,
                         <0x0 0x0 0x0 0x4 &pcie_intc_0 0x3>;
                        interrupt-map-mask = <0x0 0x0 0x0 0x7>;
                        interrupt-names = "misc";
                        interrupts = <0x0 0x48 0x4>;
                        xlnx,csr-slcr = <0x6 0x0>;
                        xlnx,num-of-bars = <0x2>;
                        xlnx,port-type = <0x1>;
                        interrupt-parent = <&gic>;
                        bus-range = <0x0 0xff>;
                        ranges = <0x2000000 0x0 0xe0010000 0x0 0xe0010000 0x0 0x10000000 0x43000000 0x80 0x0 0x80 0x0 0x0 0x80000000>;
                        msi-map = <0x0 0x84 0x0 0x10000>;
                        reg = <0x6 0x0 0x0 0x1000000 0x0 0xfca10000 0x0 0x1000 0x0 0xfca00000 0x0 0x10000>;
                        reg-names = "cfg", "cpm_slcr", "cpm_crx";
                        phandle = <0xb0>;

                        pcie_intc_0: interrupt-controller {
                                #address-cells = <0x0>;
                                #interrupt-cells = <0x1>;
                                interrupt-controller;
                                phandle = <0x83>;
                        };
                };

                cpm5_pcie: pcie@fcdd0000 {
                        device_type = "pci";
                        #address-cells = <0x3>;
                        #interrupt-cells = <0x1>;
                        #size-cells = <0x2>;
                        compatible = "xlnx,versal-cpm5-host";
                        status = "disabled";
                        interrupt-map = <0x0 0x0 0x0 0x1 &pcie_intc_2 0x0>,
                         <0x0 0x0 0x0 0x2 &pcie_intc_2 0x1>,
                         <0x0 0x0 0x0 0x3 &pcie_intc_2 0x2>,
                         <0x0 0x0 0x0 0x4 &pcie_intc_2 0x3>;
                        interrupt-map-mask = <0x0 0x0 0x0 0x7>;
                        interrupt-names = "misc";
                        interrupts = <0x0 0x48 0x4>;
                        xlnx,csr-slcr = <0xfce20000>;
                        xlnx,num-of-bars = <0x2>;
                        xlnx,port-type = <0x1>;
                        interrupt-parent = <&gic>;
                        bus-range = <0x0 0xff>;
                        ranges = <0x2000000 0x0 0xe0000000 0x0 0xe0000000 0x0 0x10000000 0x43000000 0x80 0x0 0x80 0x0 0x0 0x80000000>;
                        msi-map = <0x0 0x84 0x0 0x10000>;
                        reg = <0x6 0x0 0x0 0x1000000 0x0 0xfcdd0000 0x0 0x1000 0x0 0xfce20000 0x0 0x10000 0x0 0xfcdc0000 0x0 0x10000>;
                        reg-names = "cfg", "cpm_slcr", "cpm_csr", "cpm_crx";
                        phandle = <0xb1>;

                        pcie_intc_2: interrupt-controller {
                                #address-cells = <0x0>;
                                #interrupt-cells = <0x1>;
                                interrupt-controller;
                                phandle = <0x85>;
                        };
                };

                watchdog: watchdog@fd4d0000 {
                        compatible = "xlnx,versal-wwdt";
                        status = "disabled";
                        reg = <0x0 0xfd4d0000 0x0 0x10000>;
                        interrupt-names = "wdt", "wwdt_reset_pending", "gwdt", "gwdt_reset_pending";
                        interrupts = <0x0 0x64 0x1 0x0 0x6d 0x1 0x0 0x6c 0x1 0x0 0x6e 0x1>;
                        interrupt-parent = <&gic>;
                        timeout-sec = <0x1e>;
                        clocks = <&versal_clk 0x4c>;
                        power-domains = <&versal_firmware 0x18224029>;
                        phandle = <0xb2>;
                };

                watchdog1: watchdog@ff120000 {
                        compatible = "xlnx,versal-wwdt";
                        status = "disabled";
                        reg = <0x0 0xff120000 0x0 0x10000>;
                        interrupt-parent = <&gic>;
                        interrupt-names = "wdt", "wwdt_reset_pending", "gwdt", "gwdt_reset_pending";
                        interrupts = <0x0 0x31 0x1 0x0 0x45 0x1 0x0 0x46 0x4 0x0 0x47 0x4>;
                        timeout-sec = <0x1e>;
                        clocks = <&versal_clk 0x52>;
                        power-domains = <&versal_firmware 0x18224028>;
                        phandle = <0xb3>;
                };

                xilsem_edac: edac@f2014050 {
                        compatible = "xlnx,versal-xilsem-edac";
                        status = "disabled";
                        reg = <0x0 0xf2014050 0x0 0xc4>;
                        phandle = <0xb4>;
                };

                dma0: pmcdma@f11c0000 {
                        status = "okay";
                        compatible = "xlnx,zynqmp-csudma-1.0";
                        interrupt-parent = <&gic>;
                        interrupts = <0x0 0x83 0x4>;
                        reg = <0x0 0xf11c0000 0x0 0x10000>;
                        xlnx,dma-type = <0x1>;
                        xlnx,ip-name = "psv_pmc_dma";
                        phandle = <0x1f>;
                };

                dma1: pmcdma@f11d0000 {
                        status = "okay";
                        compatible = "xlnx,zynqmp-csudma-1.0";
                        interrupt-parent = <&gic>;
                        interrupts = <0x0 0x84 0x4>;
                        reg = <0x0 0xf11d0000 0x0 0x10000>;
                        xlnx,dma-type = <0x2>;
                        xlnx,ip-name = "psv_pmc_dma";
                        phandle = <0x20>;
                };

                coresight: coresight@f0800000 {
                        compatible = "xlnx,coresight-1.0";
                        status = "okay";
                        reg = <0x0 0xf0800000 0x0 0x10000>;
                        xlnx,ip-name = "psv_coresight";
                        phandle = <0xb>;
                };

                gic: interrupt-controller@f9000000 {
                        phandle = <0x33>;
                        xlnx,ip-name = "psv_acpu_gic";
                        status = "okay";
                        interrupts = <0x1 0x9 0x4>;
                        interrupt-parent = <&gic>;
                        interrupt-controller;
                        reg = <0x0 0xf9000000 0x0 0x80000 0x0 0xf9080000 0x0 0x80000>;
                        ranges;
                        #size-cells = <0x2>;
                        #address-cells = <0x2>;
                        #interrupt-cells = <0x3>;
                        compatible = "arm,gic-v3";

                        gic_its: msi-controller@f9020000 {
                                phandle = <0x84>;
                                reg = <0x0 0xf9020000 0x0 0x20000>;
                                #msi-cells = <0x1>;
                                msi-controller;
                                status = "disabled";
                                compatible = "arm,gic-v3-its";
                        };
                };
        };

        amba_xppu: indirect-bus@1 {
                compatible = "indirect-bus";
                #address-cells = <0x2>;
                #size-cells = <0x2>;
                phandle = <0x120>;

                lpd_xppu: xppu@ff990000 {
                        compatible = "xlnx,xppu";
                        #firewall-cells = <0x0>;
                        reg = <0x0 0xff990000 0x0 0x2000>;
                        status = "okay";
                        xlnx,ip-name = "psv_lpd_xppu";
                        phandle = <0x51>;
                };

                pmc_xppu: xppu@f1310000 {
                        compatible = "xlnx,xppu";
                        #firewall-cells = <0x0>;
                        reg = <0x0 0xf1310000 0x0 0x2000>;
                        status = "okay";
                        xlnx,ip-name = "psv_pmc_xppu";
                        phandle = <0x30>;
                };

                pmc_xppu_npi: xppu@f1300000 {
                        compatible = "xlnx,xppu";
                        #firewall-cells = <0x0>;
                        reg = <0x0 0xf1300000 0x0 0x2000>;
                        status = "okay";
                        xlnx,ip-name = "psv_pmc_xppu_npi";
                        phandle = <0x2f>;
                };
        };

        amba_xmpu: indirect-bus@2 {
                compatible = "indirect-bus";
                #address-cells = <0x2>;
                #size-cells = <0x2>;
                phandle = <0x121>;

                fpd_xmpu: xmpu@fd390000 {
                        compatible = "xlnx,xmpu";
                        #firewall-cells = <0x0>;
                        reg = <0x0 0xfd390000 0x0 0x1000>;
                        status = "okay";
                        xlnx,ip-name = "psv_fpd_slave_xmpu";
                        phandle = <0x38>;
                };

                pmc_xmpu: xmpu@f12f0000 {
                        compatible = "xlnx,xmpu";
                        #firewall-cells = <0x0>;
                        reg = <0x0 0xf12f0000 0x0 0x1000>;
                        status = "okay";
                        xlnx,ip-name = "psv_pmc_xmpu";
                        phandle = <0x2e>;
                };

                ocm_xmpu: xmpu@ff980000 {
                        compatible = "xlnx,xmpu";
                        #firewall-cells = <0x0>;
                        reg = <0x0 0xff980000 0x0 0x1000>;
                        status = "okay";
                        xlnx,ip-name = "psv_ocm_xmpu";
                        phandle = <0x50>;
                };

                ddrmc_xmpu_0: xmpu@f6080000 {
                        compatible = "xlnx,xmpu";
                        #firewall-cells = <0x0>;
                        reg = <0x0 0xf6080000 0x0 0x1000>;
                        status = "disabled";
                        phandle = <0x122>;
                };

                ddrmc_xmpu_1: xmpu@f6220000 {
                        compatible = "xlnx,xmpu";
                        #firewall-cells = <0x0>;
                        reg = <0x0 0xf6220000 0x0 0x1000>;
                        status = "disabled";
                        phandle = <0x123>;
                };

                ddrmc_xmpu_2: xmpu@f6390000 {
                        compatible = "xlnx,xmpu";
                        #firewall-cells = <0x0>;
                        reg = <0x0 0xf6390000 0x0 0x1000>;
                        status = "disabled";
                        phandle = <0x124>;
                };

                ddrmc_xmpu_3: xmpu@f6500000 {
                        compatible = "xlnx,xmpu";
                        #firewall-cells = <0x0>;
                        reg = <0x0 0xf6500000 0x0 0x1000>;
                        status = "disabled";
                        phandle = <0x125>;
                };
        };

        pl_alt_ref: pl-alt-ref {
                bootph-all;
                compatible = "fixed-clock";
                #clock-cells = <0x0>;
                clock-frequency = <0x1fca055>;
                clock-output-names = "pl_alt_ref_clk";
                phandle = <0x87>;
        };

        ref: ref {
                bootph-all;
                compatible = "fixed-clock";
                #clock-cells = <0x0>;
                clock-frequency = <0x1fca055>;
                clock-output-names = "ref_clk";
                phandle = <0x86>;
        };

        can0_clk: can0-clk {
                #clock-cells = <0x0>;
                compatible = "fixed-factor-clock";
                clocks = <&versal_clk 0x60>;
                clock-div = <0x2>;
                clock-mult = <0x1>;
                clock-output-names = "can0_clk";
                phandle = <0x7e>;
        };

        can1_clk: can1-clk {
                #clock-cells = <0x0>;
                compatible = "fixed-factor-clock";
                clocks = <&versal_clk 0x61>;
                clock-div = <0x2>;
                clock-mult = <0x1>;
                clock-output-names = "can1_clk";
                phandle = <0x7f>;
        };

        firmware {

                versal_firmware: versal-firmware {
                        compatible = "xlnx,versal-firmware";
                        interrupt-parent = <&gic>;
                        bootph-all;
                        method = "smc";
                        #power-domain-cells = <0x1>;
                        phandle = <0x63>;

                        versal_clk: clock-controller {
                                bootph-all;
                                #clock-cells = <0x1>;
                                compatible = "xlnx,versal-clk";
                                clocks = <&ref>,
                                 <&pl_alt_ref>;
                                clock-names = "ref", "pl_alt_ref";
                                phandle = <0x64>;
                        };

                        zynqmp_power: power-management {
                                compatible = "xlnx,zynqmp-power";
                                phandle = <0x126>;
                        };

                        versal_reset: reset-controller {
                                compatible = "xlnx,versal-reset";
                                #reset-cells = <0x1>;
                                phandle = <0x82>;
                        };

                        pinctrl0: pinctrl {
                                compatible = "xlnx,versal-pinctrl";
                                phandle = <0x127>;
                        };

                        versal_sec_cfg: versal-sec-cfg {
                                compatible = "xlnx,versal-sec-cfg";
                                #address-cells = <0x1>;
                                #size-cells = <0x1>;
                                phandle = <0x128>;

                                nvmem-layout {
                                        compatible = "fixed-layout";
                                        #address-cells = <0x1>;
                                        #size-cells = <0x1>;

                                        bbram_zeroize: bbram-zeroize@4 {
                                                reg = <0x4 0x4>;
                                                phandle = <0x129>;
                                        };

                                        bbram_key: bbram-key@10 {
                                                reg = <0x10 0x20>;
                                                phandle = <0x12a>;
                                        };

                                        bbram_usr: bbram-usr@30 {
                                                reg = <0x30 0x4>;
                                                phandle = <0x12b>;
                                        };

                                        bbram_lock: bbram-lock@48 {
                                                reg = <0x48 0x4>;
                                                phandle = <0x12c>;
                                        };

                                        user_key0: user-key@110 {
                                                reg = <0x110 0x20>;
                                                phandle = <0x12d>;
                                        };

                                        user_key1: user-key@130 {
                                                reg = <0x130 0x20>;
                                                phandle = <0x12e>;
                                        };

                                        user_key2: user-key@150 {
                                                reg = <0x150 0x20>;
                                                phandle = <0x12f>;
                                        };

                                        user_key3: user-key@170 {
                                                reg = <0x170 0x20>;
                                                phandle = <0x130>;
                                        };

                                        user_key4: user-key@190 {
                                                reg = <0x190 0x20>;
                                                phandle = <0x131>;
                                        };

                                        user_key5: user-key@1b0 {
                                                reg = <0x1b0 0x20>;
                                                phandle = <0x132>;
                                        };

                                        user_key6: user-key@1d0 {
                                                reg = <0x1d0 0x20>;
                                                phandle = <0x133>;
                                        };

                                        user_key7: user-key@1f0 {
                                                reg = <0x1f0 0x20>;
                                                phandle = <0x134>;
                                        };
                                };
                        };
                };
        };

        axi_noc2_0_ddr_memory: memory@00000000 {
                compatible = "xlnx,axi-noc2-1.1";
                xlnx,ip-name = "axi_noc2";
                device_type = "memory";
                reg = <0x0 0x0 0x0 0x80000000>;
                memory_type = "memory";
                phandle = <0x3>;
        };

        chosen {
                stdout-path = "serial0:115200";
                bootargs = "console=ttyAMA0 earlycon=pl011,mmio32,0xFF000000,115200n8";
        };

        aliases {
                serial0 = "/axi/serial@ff000000";
                spi0 = "/axi/spi@f1030000";
                ethernet1 = "/axi/ethernet@ff0d0000";
                serial1 = "/axi/coresight@f0800000";
                i2c0 = "/axi/i2c@ff030000";
                ethernet0 = "/axi/ethernet@ff0c0000";
                serial2 = "/dcc";
                mmc0 = "/axi/mmc@f1050000";
                usb0 = "/axi/usb@ff9d0000";
                rtc0 = "/axi/rtc@f12a0000";
        };

        __symbols__ {
                cpus_a72 = "/cpus-a72@0";
                psv_cortexa72_0 = "/cpus-a72@0/cpu@0";
                psv_cortexa72_1 = "/cpus-a72@0/cpu@1";
                CPU_SLEEP_0 = "/cpus-a72@0/idle-states/cpu-sleep-0";
                cpu_opp_table = "/opp-table-cpu";
                dcc = "/dcc";
                fpga = "/fpga-region";
                psci = "/psci";
                timer = "/timer";
                versal_fpga = "/versal-fpga";
                sensor0 = "/versal-thermal-sensor";
                versal_thermal = "/thermal-zones/versal-thermal";
                temp_alert = "/thermal-zones/versal-thermal/trips/temp-alert";
                ot_crit = "/thermal-zones/versal-thermal/trips/ot-crit";
                amba_apu = "/apu-bus";
                gic_its = "/axi/interrupt-controller@f9000000/msi-controller@f9020000";
                amba = "/axi";
                imux = "/axi/interrupt-multiplex";
                can0 = "/axi/can@ff060000";
                can1 = "/axi/can@ff070000";
                cci = "/axi/cci@fd000000";
                cci_pmu = "/axi/cci@fd000000/pmu@10000";
                lpd_dma_chan0 = "/axi/dma-controller@ffa80000";
                lpd_dma_chan1 = "/axi/dma-controller@ffa90000";
                lpd_dma_chan2 = "/axi/dma-controller@ffaa0000";
                lpd_dma_chan3 = "/axi/dma-controller@ffab0000";
                lpd_dma_chan4 = "/axi/dma-controller@ffac0000";
                lpd_dma_chan5 = "/axi/dma-controller@ffad0000";
                lpd_dma_chan6 = "/axi/dma-controller@ffae0000";
                lpd_dma_chan7 = "/axi/dma-controller@ffaf0000";
                gem0 = "/axi/ethernet@ff0c0000";
                mdio = "/axi/ethernet@ff0c0000/mdio";
                phy1 = "/axi/ethernet@ff0c0000/mdio/phy@1";
                phy2 = "/axi/ethernet@ff0c0000/mdio/phy@2";
                gem1 = "/axi/ethernet@ff0d0000";
                gpio0 = "/axi/gpio@ff0b0000";
                gpio1 = "/axi/gpio@f1020000";
                i2c0 = "/axi/i2c@ff020000";
                i2c1 = "/axi/i2c@ff030000";
                eeprom_versal = "/axi/i2c@ff030000/eeprom@51";
                i2c2 = "/axi/i2c@f1000000";
                mc0 = "/axi/memory-controller@f6150000";
                mc1 = "/axi/memory-controller@f62c0000";
                mc2 = "/axi/memory-controller@f6430000";
                mc3 = "/axi/memory-controller@f65a0000";
                ocm = "/axi/memory-controller@ff960000";
                rtc = "/axi/rtc@f12a0000";
                sdhci0 = "/axi/mmc@f1040000";
                sdhci1 = "/axi/mmc@f1050000";
                serial0 = "/axi/serial@ff000000";
                serial1 = "/axi/serial@ff010000";
                smmu = "/axi/iommu@fd800000";
                ospi = "/axi/spi@f1010000";
                qspi = "/axi/spi@f1030000";
                spi0 = "/axi/spi@ff040000";
                spi1 = "/axi/spi@ff050000";
                sysmon0 = "/axi/sysmon@f1270000";
                sysmon1 = "/axi/sysmon@109270000";
                sysmon2 = "/axi/sysmon@111270000";
                sysmon3 = "/axi/sysmon@119270000";
                ttc0 = "/axi/timer@ff0e0000";
                ttc1 = "/axi/timer@ff0f0000";
                ttc2 = "/axi/timer@ff100000";
                ttc3 = "/axi/timer@ff110000";
                usb0 = "/axi/usb@ff9d0000";
                dwc3_0 = "/axi/usb@ff9d0000/usb@fe200000";
                cpm_pciea = "/axi/pci@fca10000";
                pcie_intc_0 = "/axi/pci@fca10000/interrupt-controller";
                cpm5_pcie = "/axi/pcie@fcdd0000";
                pcie_intc_2 = "/axi/pcie@fcdd0000/interrupt-controller";
                watchdog = "/axi/watchdog@fd4d0000";
                watchdog1 = "/axi/watchdog@ff120000";
                xilsem_edac = "/axi/edac@f2014050";
                dma0 = "/axi/pmcdma@f11c0000";
                dma1 = "/axi/pmcdma@f11d0000";
                coresight = "/axi/coresight@f0800000";
                amba_xppu = "/indirect-bus@1";
                lpd_xppu = "/indirect-bus@1/xppu@ff990000";
                pmc_xppu = "/indirect-bus@1/xppu@f1310000";
                pmc_xppu_npi = "/indirect-bus@1/xppu@f1300000";
                amba_xmpu = "/indirect-bus@2";
                fpd_xmpu = "/indirect-bus@2/xmpu@fd390000";
                pmc_xmpu = "/indirect-bus@2/xmpu@f12f0000";
                ocm_xmpu = "/indirect-bus@2/xmpu@ff980000";
                ddrmc_xmpu_0 = "/indirect-bus@2/xmpu@f6080000";
                ddrmc_xmpu_1 = "/indirect-bus@2/xmpu@f6220000";
                ddrmc_xmpu_2 = "/indirect-bus@2/xmpu@f6390000";
                ddrmc_xmpu_3 = "/indirect-bus@2/xmpu@f6500000";
                pl_alt_ref = "/pl-alt-ref";
                ref = "/ref";
                can0_clk = "/can0-clk";
                can1_clk = "/can1-clk";
                versal_firmware = "/firmware/versal-firmware";
                versal_clk = "/firmware/versal-firmware/clock-controller";
                zynqmp_power = "/firmware/versal-firmware/power-management";
                versal_reset = "/firmware/versal-firmware/reset-controller";
                pinctrl0 = "/firmware/versal-firmware/pinctrl";
                versal_sec_cfg = "/firmware/versal-firmware/versal-sec-cfg";
                bbram_zeroize = "/firmware/versal-firmware/versal-sec-cfg/nvmem-layout/bbram-zeroize@4";
                bbram_key = "/firmware/versal-firmware/versal-sec-cfg/nvmem-layout/bbram-key@10";
                bbram_usr = "/firmware/versal-firmware/versal-sec-cfg/nvmem-layout/bbram-usr@30";
                bbram_lock = "/firmware/versal-firmware/versal-sec-cfg/nvmem-layout/bbram-lock@48";
                user_key0 = "/firmware/versal-firmware/versal-sec-cfg/nvmem-layout/user-key@110";
                user_key1 = "/firmware/versal-firmware/versal-sec-cfg/nvmem-layout/user-key@130";
                user_key2 = "/firmware/versal-firmware/versal-sec-cfg/nvmem-layout/user-key@150";
                user_key3 = "/firmware/versal-firmware/versal-sec-cfg/nvmem-layout/user-key@170";
                user_key4 = "/firmware/versal-firmware/versal-sec-cfg/nvmem-layout/user-key@190";
                user_key5 = "/firmware/versal-firmware/versal-sec-cfg/nvmem-layout/user-key@1b0";
                user_key6 = "/firmware/versal-firmware/versal-sec-cfg/nvmem-layout/user-key@1d0";
                user_key7 = "/firmware/versal-firmware/versal-sec-cfg/nvmem-layout/user-key@1f0";
                axi_noc2_0_ddr_memory = "/memory@00000000";
                gic = "/axi/interrupt-controller@f9000000";
        };
};
